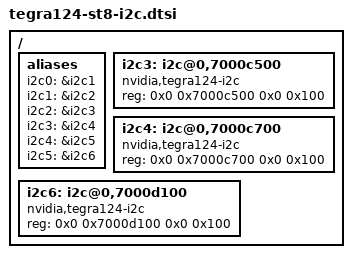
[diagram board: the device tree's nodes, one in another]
#include "tegra124-st8-i2c-sensors.dtsi"
#include "tegra124-st8-i2c-battery.dtsi"
#include "tegra124-st8-i2c-palmas_tps65913.dtsi"

/ {
    aliases {
        i2c0 = &i2c1;
        i2c1 = &i2c2;
        i2c2 = &i2c3;
        i2c3 = &i2c4;
        i2c4 = &i2c5;
        i2c5 = &i2c6;
    };
    
    // eMMC I2C? DSI DDC?
    i2c3: i2c@0,7000c500 {
        #address-cells = <0x1>;
        #size-cells = <0x0>;
        status = "okay";
        compatible = "nvidia,tegra124-i2c";
        reg = <0x0 0x7000c500 0x0 0x100>;
    };

    // HDMI DDC
    i2c4: i2c@0,7000c700 {
        #address-cells = <0x1>;
        #size-cells = <0x0>;
        status = "okay";
        compatible = "nvidia,tegra124-i2c";
        reg = <0x0 0x7000c700 0x0 0x100>;
    };

    i2c6: i2c@0,7000d100 {
        #address-cells = <0x1>;
        #size-cells = <0x0>;
        status = "okay";
        compatible = "nvidia,tegra124-i2c";
        reg = <0x0 0x7000d100 0x0 0x100>;
    };
};
